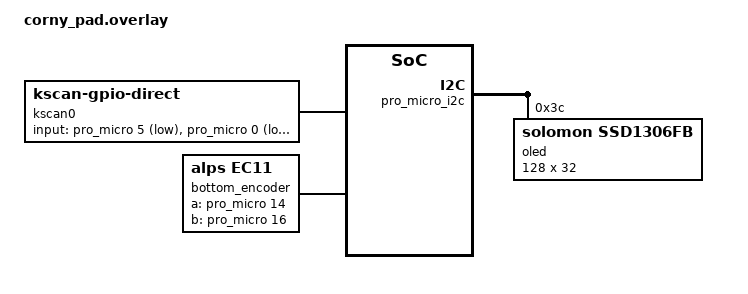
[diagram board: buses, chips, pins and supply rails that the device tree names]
#include "corny.dtsi"

&default_transform {
    col-offset = <12>;
};

/ {
    chosen {
        zmk,kscan = &kscan0;
    };

    kscan0: kscan_direct {
        compatible = "zmk,kscan-gpio-direct";
        wakeup-source;

    input-gpios
        = <&pro_micro 5 (GPIO_ACTIVE_LOW | GPIO_PULL_UP)>
        , <&pro_micro 0 (GPIO_ACTIVE_LOW | GPIO_PULL_UP)>
        , <&pro_micro 1 (GPIO_ACTIVE_LOW | GPIO_PULL_UP)>
        , <&pro_micro 8 (GPIO_ACTIVE_LOW | GPIO_PULL_UP)>
        , <&pro_micro 7 (GPIO_ACTIVE_LOW | GPIO_PULL_UP)>
        , <&pro_micro 6 (GPIO_ACTIVE_LOW | GPIO_PULL_UP)>
        , <&pro_micro 21 (GPIO_ACTIVE_LOW | GPIO_PULL_UP)>
        , <&pro_micro 9 (GPIO_ACTIVE_LOW | GPIO_PULL_UP)>
        , <&pro_micro 20 (GPIO_ACTIVE_LOW | GPIO_PULL_UP)>
        , <&pro_micro 10 (GPIO_ACTIVE_LOW | GPIO_PULL_UP)>
        ;
    };

    bottom_encoder: encoder_bottom {
        compatible = "alps,ec11";
        a-gpios = <&pro_micro 14 (GPIO_ACTIVE_HIGH | GPIO_PULL_UP)>;
        b-gpios = <&pro_micro 16 (GPIO_ACTIVE_HIGH | GPIO_PULL_UP)>;
        steps = <80>;
        status = "okay";
    };
    sensors: sensors {
        compatible = "zmk,keymap-sensors";
        sensors = <&bottom_encoder>;
        triggers-per-rotation = <20>;
    };
};

&pro_micro_i2c {
    status = "okay";

    oled: ssd1306@3c {
        compatible = "solomon,ssd1306fb";
        reg = <0x3c>;
        width = <128>;
        height = <32>;
        segment-offset = <0>;
        page-offset = <0>;
        display-offset = <0>;
        multiplex-ratio = <31>;
        segment-remap;
        com-invdir;
        com-sequential;
        inversion-on;
        prechargep = <0x22>;
    };
};
